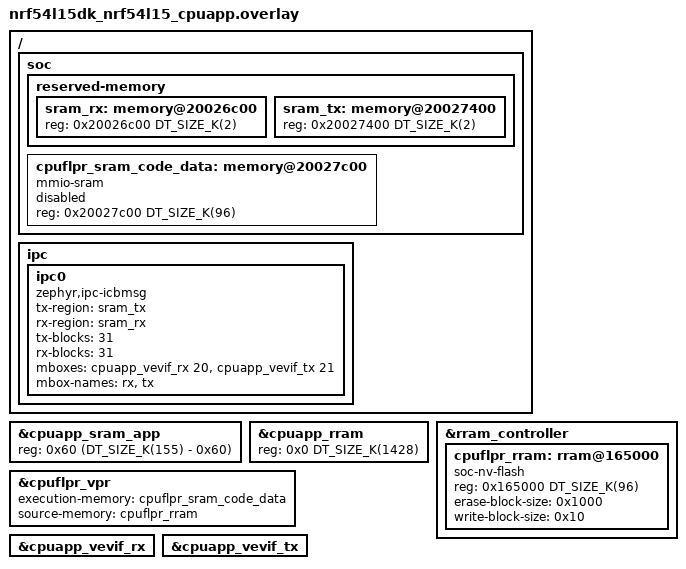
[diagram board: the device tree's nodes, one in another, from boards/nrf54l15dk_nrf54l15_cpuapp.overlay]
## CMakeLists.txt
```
#
# Copyright (c) 2022 Nordic Semiconductor ASA
#
# SPDX-License-Identifier: Apache-2.0
#

cmake_minimum_required(VERSION 3.28.0)

find_package(Zephyr REQUIRED HINTS $ENV{ZEPHYR_BASE})

if(NOT (CONFIG_BOARD_NRF5340DK_NRF5340_CPUAPP OR
   CONFIG_BOARD_NRF5340BSIM_NRF5340_CPUAPP OR
   CONFIG_BOARD_NRF54L15DK_NRF54L15_CPUAPP))
  message(FATAL_ERROR "${BOARD}/${BOARD_QUALIFIERS} is not supported for this sample")
endif()

project(log_multidomain)

target_sources(app PRIVATE src/main.c)
```

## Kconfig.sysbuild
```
# Copyright 2023 Nordic Semiconductor ASA
#
# SPDX-License-Identifier: Apache-2.0

source "share/sysbuild/Kconfig"

config NET_CORE_BOARD
string
	default "nrf5340dk/nrf5340/cpunet" if $(BOARD) = "nrf5340dk"
	default "nrf5340bsim/nrf5340/cpunet" if $(BOARD_TARGET_STRING) = "NRF5340BSIM_NRF5340_CPUAPP"
	default "nrf54l15dk/nrf54l15/cpuflpr" if $(BOARD_TARGET_STRING) = "NRF54L15DK_NRF54L15_CPUAPP"
```

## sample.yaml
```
sample:
  name: Logging in multi-domain environment
common:
  sysbuild: true
  tags: ipc
tests:
  sample.logging.multidomain.ipc_static_vrings:
    platform_allow:
      - nrf5340dk/nrf5340/cpuapp
      - nrf5340bsim/nrf5340/cpuapp
    integration_platforms:
      - nrf5340dk/nrf5340/cpuapp
      - nrf5340bsim/nrf5340/cpuapp
    harness: console
    harness_config:
      type: multi_line
      ordered: false
      regex:
        - "Hello World!"
        - "app: IPC-service HOST \\[INST 1\\] demo started"
        - "app: loop: 0"
        - "app: ipc open"
        - "app: wait for bound"
        - "app: bounded"
        - "app: REMOTE \\[1\\]: 0"
        - "app: HOST \\[1\\]: 1"
        - "app: IPC-service HOST \\[INST 1\\] demo ended."
```

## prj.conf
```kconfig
CONFIG_PRINTK=y
CONFIG_HEAP_MEM_POOL_SIZE=4096

CONFIG_IPC_SERVICE=y
CONFIG_MBOX=y

CONFIG_LOG=y
CONFIG_LOG_BUFFER_SIZE=8192
CONFIG_LOG_MULTIDOMAIN=y
CONFIG_LOG_LINK_IPC=y
CONFIG_IPC_SERVICE_LOG_LEVEL_INF=y

# Use asynchronous API for UART backend to reduce CPU load.
CONFIG_UART_ASYNC_API=y
CONFIG_LOG_BACKEND_UART_ASYNC=y

CONFIG_ASSERT=y
CONFIG_LOG_PRINTK=n

CONFIG_CPU_LOAD=y
```

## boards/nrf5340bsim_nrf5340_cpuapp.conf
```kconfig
# For the mailbox to be initialized logger initialization is delayed like in real HW
CONFIG_LOG_PROCESS_THREAD=y
CONFIG_LOG_MODE_DEFERRED=y
```

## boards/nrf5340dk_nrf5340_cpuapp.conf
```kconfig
CONFIG_SOC_NRF53_CPUNET_ENABLE=y

CONFIG_OPENAMP=y
CONFIG_OPENAMP_SLAVE=n
```

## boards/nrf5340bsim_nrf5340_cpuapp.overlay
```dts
/*
 * Copyright (c) 2023 Nordic Semiconductor ASA
 *
 * SPDX-License-Identifier: Apache-2.0
 */

#include "nrf5340dk_nrf5340_cpuapp.overlay"
```

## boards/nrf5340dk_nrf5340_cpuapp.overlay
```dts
/*
 * Copyright (c) 2026 Nordic Semiconductor ASA
 *
 * SPDX-License-Identifier: Apache-2.0
 */

#include "nrf5340dk_nrf5340_cpuapp_common.dtsi"

/ {
	reserved-memory {
		ranges;
		#address-cells = <1>;
		#size-cells = <1>;

		sram_tx: memory@20070000 {
			reg = <0x20070000 DT_SIZE_K(32)>;
		};

		sram_rx: memory@20078000 {
			reg = <0x20078000 DT_SIZE_K(32)>;
		};
	};

	ipc {
		ipc0: ipc0 {
			compatible = "zephyr,ipc-icbmsg";
			dcache-alignment = <8>;
			tx-region = <&sram_tx>;
			rx-region = <&sram_rx>;
			tx-blocks = <20>;
			rx-blocks = <20>;
			mboxes = <&mbox 0>, <&mbox 1>;
			mbox-names = "tx", "rx";
			status = "okay";
		};
	};
};
```

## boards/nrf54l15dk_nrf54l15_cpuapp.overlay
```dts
/*
 * Copyright (c) 2026 Nordic Semiconductor ASA
 *
 * SPDX-License-Identifier: Apache-2.0
 */

/* 256k RAM layout:
 * - 155k APP RAM
 * - 2k FLPR to APP IPC buffers
 * - 2k APP to FLPR IPC buffers
 * - 96k FLPR code and data
 * - 1k FLPR hibernation space
 */

/ {
	soc {
		reserved-memory {
			#address-cells = <1>;
			#size-cells = <1>;

			sram_rx: memory@20026c00 {
				reg = <0x20026c00 DT_SIZE_K(2)>;
			};

			sram_tx: memory@20027400 {
				reg = <0x20027400 DT_SIZE_K(2)>;
			};
		};

		cpuflpr_sram_code_data: memory@20027c00 {
			compatible = "mmio-sram";
			reg = <0x20027c00 DT_SIZE_K(96)>;
			ranges = <0x0 0x20027c00 DT_SIZE_K(96)>;
			status = "reserved";
			#address-cells = <1>;
			#size-cells = <1>;
		};
	};

	ipc {
		ipc0: ipc0 {
			compatible = "zephyr,ipc-icbmsg";
			tx-region = <&sram_tx>;
			rx-region = <&sram_rx>;
			tx-blocks = <31>;
			rx-blocks = <31>;
			mboxes = <&cpuapp_vevif_rx 20>, <&cpuapp_vevif_tx 21>;
			mbox-names = "rx", "tx";
			status = "okay";
		};
	};
};

&cpuapp_sram_app {
	reg = <0x60 (DT_SIZE_K(155) - 0x60)>;
};

&cpuapp_rram {
	reg = <0x0 DT_SIZE_K(1428)>;
	ranges = <0x0 0x0 DT_SIZE_K(1428)>;

	/delete-node/ partitions;
};

&rram_controller {
	cpuflpr_rram: rram@165000 {
		compatible = "soc-nv-flash";
		reg = <0x165000 DT_SIZE_K(96)>;
		ranges = <0x0 0x165000 DT_SIZE_K(96)>;
		erase-block-size = <0x1000>;
		write-block-size = <0x10>;
		#address-cells = <1>;
		#size-cells = <1>;
	};
};

&cpuflpr_vpr {
	status = "okay";
	execution-memory = <&cpuflpr_sram_code_data>;
	source-memory = <&cpuflpr_rram>;
};

&cpuapp_vevif_rx {
	status = "okay";
};

&cpuapp_vevif_tx {
	status = "okay";
};

#define WITH_FLPR_PARTITIONS
#include <vendor/nordic/nrf54l15_cpuapp_partition.dtsi>
```

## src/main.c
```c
/*
 * Copyright (c) 2022 Nordic Semiconductor ASA
 *
 * SPDX-License-Identifier: Apache-2.0
 */

#include <zephyr/kernel.h>
#include <zephyr/sys/printk.h>
#include <zephyr/logging/log.h>
#include <zephyr/ipc/ipc_service.h>
#include <zephyr/sys/cpu_load.h>
LOG_MODULE_REGISTER(app);

static volatile uint8_t sample_received_data;
static volatile bool ipc_ready;
static volatile bool ipc_bound;

static void timeout(struct k_timer *timer)
{
	static int cnt;

	LOG_INF("loop: %d", cnt++);
	if (cnt < 10) {
		k_timer_start(timer, K_MSEC(40), K_NO_WAIT);
	}
}

K_TIMER_DEFINE(timeout_timer, timeout, NULL);

static void ready_notify(volatile bool *ready)
{
	*ready = true;
}

static void ready_wait(volatile bool *ready)
{
	while (!*ready) {
		k_msleep(1);
	}
	*ready = false;
}
/*
 * ==> THREAD 1 (IPC instance 1) <==
 */

static void ept_bound(void *priv)
{
	ready_notify(&ipc_bound);
}

static void ept_recv(const void *data, size_t len, void *priv)
{
	sample_received_data = *((uint8_t *)data);

	ready_notify(&ipc_ready);
}

static const struct ipc_ept_cfg ept_cfg = {
	.name = "sample",
	.cb = {
			.bound = ept_bound,
			.received = ept_recv,
	},
};

static void ipc_run(void)
{
	const struct device *ipc_instance;
	unsigned char message = 0;
	struct ipc_ept ept;
	int ret;

	LOG_INF("Multidomain logging HOST demo started");

	k_sleep(K_MSEC(1000));

	ipc_instance = DEVICE_DT_GET(DT_NODELABEL(ipc0));

	ret = ipc_service_open_instance(ipc_instance);
	if (ret < 0 && ret != -EALREADY) {
		LOG_ERR("ipc_service_open_instance() failure");
		return;
	}

	ret = ipc_service_register_endpoint(ipc_instance, &ept, &ept_cfg);
	if (ret < 0) {
		LOG_ERR("ipc_service_register_endpoint() failure");
		return;
	}

	ready_wait(&ipc_bound);

	while (message < 10) {
		ret = ipc_service_send(&ept, &message, sizeof(message));
		if (ret < 0) {
			LOG_ERR("send_message(%d) failed with ret %d", message, ret);
			break;
		}

		ready_wait(&ipc_ready);
		message = sample_received_data;

		LOG_INF("HOST [1]: %d", message);
		message++;

		k_msleep(10);
	}

	LOG_INF("Multidomain logging HOST demo ended.");

	if (IS_ENABLED(CONFIG_CPU_LOAD)) {
		int load = cpu_load_get(true);

		LOG_INF("CPU load: %d.%d%%", load / 10, load % 10);
	}
}

int main(void)
{
	if (IS_ENABLED(CONFIG_CPU_LOAD)) {
		(void)cpu_load_get(true);
	}

	printk("Hello World! %s\n", CONFIG_BOARD);

	k_timer_start(&timeout_timer, K_MSEC(40), K_NO_WAIT);

	ipc_run();

	return 0;
}
```

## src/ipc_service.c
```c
/*
 * Copyright (c) 2022 Nordic Semiconductor ASA
 *
 * SPDX-License-Identifier: Apache-2.0
 */

#include <zephyr/kernel.h>
#include <zephyr/device.h>
#include <zephyr/ipc/ipc_service.h>
#include <zephyr/logging/log.h>
#include <zephyr/sys/cpu_load.h>
LOG_MODULE_DECLARE(app);

#define STACKSIZE	4096
#define PRIORITY	K_PRIO_PREEMPT(2)

K_THREAD_STACK_DEFINE(sample_stack, STACKSIZE);
static volatile uint8_t sample_received_data;
static K_SEM_DEFINE(bound_sem, 0, 1);
static K_SEM_DEFINE(data_sem, 0, 1);

/*
 * ==> THREAD 1 (IPC instance 1) <==
 */

static void ept_bound(void *priv)
{
	k_sem_give(&bound_sem);
}

static void ept_recv(const void *data, size_t len, void *priv)
{
	sample_received_data = *((uint8_t *) data);

	k_sem_give(&data_sem);
}

static struct ipc_ept_cfg ept_cfg = {
	.name = "sample",
	.cb = {
		.bound    = ept_bound,
		.received = ept_recv,
	},
};

static void sample_entry(void *dummy0, void *dummy1, void *dummy2)
{
	ARG_UNUSED(dummy0);
	ARG_UNUSED(dummy1);
	ARG_UNUSED(dummy2);

	const struct device *ipc_instance;
	unsigned char message = 0;
	struct ipc_ept ept;
	int ret;
	int load = 0;

	LOG_INF("Multidomain logging HOST demo started");

	k_sleep(K_MSEC(1000));

	ipc_instance = DEVICE_DT_GET(DT_NODELABEL(ipc0));

	ret = ipc_service_open_instance(ipc_instance);
	if (ret < 0 && ret != -EALREADY) {
		LOG_ERR("ipc_service_open_instance() failure");
		return;
	}

	ret = ipc_service_register_endpoint(ipc_instance, &ept, &ept_cfg);
	if (ret < 0) {
		LOG_ERR("ipc_service_register_endpoint() failure");
		return;
	}

	k_sem_take(&bound_sem, K_FOREVER);

	if (IS_ENABLED(CONFIG_CPU_LOAD)) {
		(void)cpu_load_get(true);
	}

	while (message < 20) {
		ret = ipc_service_send(&ept, &message, sizeof(message));
		if (ret < 0) {
			LOG_ERR("send_message(%d) failed with ret %d", message, ret);
			break;
		}

		k_sem_take(&data_sem, K_FOREVER);
		message = sample_received_data;

		LOG_INF("HOST [1]: %d", message);
		message++;

		k_msleep(10);
		if (message % 10 == 0) {
			if (IS_ENABLED(CONFIG_CPU_LOAD)) {
				load = cpu_load_get(true);
				LOG_INF("CPU load: %d.%d%%", load / 10, load % 10);
			}
		}
	}

	LOG_INF("Multidomain logging HOST demo ended.");
}

K_THREAD_DEFINE(sample_thread_id, STACKSIZE, sample_entry, NULL, NULL, NULL, PRIORITY, 0, 0);
```
